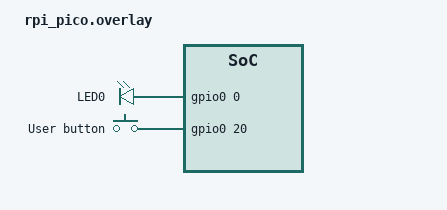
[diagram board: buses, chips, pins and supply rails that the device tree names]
/ {
    aliases {
        led = &led0;
        btn = &button0;
    };
    leds {
             compatible = "gpio-leds";
             led0: led_0 {
                     gpios = <&gpio0 0 GPIO_ACTIVE_HIGH>;
                     label = "LED0";
             };
     };

     buttons {
             compatible = "gpio-keys";
             button0: button_0 {
                     gpios = < &gpio0 20 GPIO_ACTIVE_HIGH>;
                     label = "User button";
             };
     };
};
